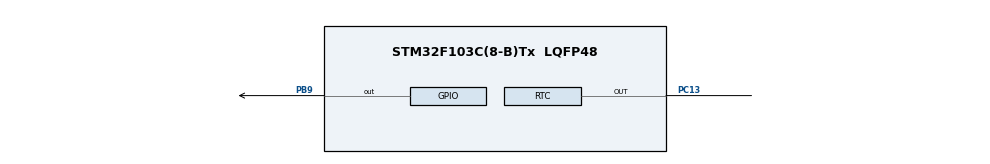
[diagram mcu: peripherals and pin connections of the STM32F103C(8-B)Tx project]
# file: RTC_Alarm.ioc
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Mcu.Family=STM32F1
Mcu.Name=STM32F103C(8-B)Tx
Mcu.Package=LQFP48
NVIC.PriorityGroup=NVIC_PRIORITYGROUP_4
NVIC.RTC_Alarm_IRQn=true\:0\:0\:false\:false\:true\:true
PA13.Mode=Serial_Wire
PA13.Signal=SYS_JTMS-SWDIO
PA14.Mode=Serial_Wire
PA14.Signal=SYS_JTCK-SWCLK
PB9.GPIO_ModeDefaultOutputPP=GPIO_MODE_OUTPUT_PP
PB9.GPIO_PuPd=GPIO_NOPULL
PB9.GPIO_Speed=GPIO_SPEED_FREQ_HIGH
PB9.PinState=GPIO_PIN_SET
PB9.Signal=GPIO_Output
PC13-TAMPER-RTC.Mode=RTC OUT
PC13-TAMPER-RTC.Signal=RTC_OUT
PD0-OSC_IN.Mode=HSE-External-Oscillator
PD0-OSC_IN.Signal=RCC_OSC_IN
PD1-OSC_OUT.Mode=HSE-External-Oscillator
PD1-OSC_OUT.Signal=RCC_OSC_OUT
ProjectManager.HeapSize=0x400
ProjectManager.StackSize=0x600
ProjectManager.TargetToolchain=MDK-ARM V5
RCC.AHBFreq_Value=72000000
RCC.APB1CLKDivider=RCC_HCLK_DIV2
RCC.APB1Freq_Value=36000000
RCC.APB1TimFreq_Value=72000000
RCC.APB2Freq_Value=72000000
RCC.APB2TimFreq_Value=72000000
RCC.EnbaleCSS=true
RCC.HCLKFreq_Value=72000000
RCC.HSE_VALUE=12000000
RCC.PLLMUL=RCC_PLL_MUL6
RCC.PLLSourceVirtual=RCC_PLLSOURCE_HSE
RCC.PREFETCH_ENABLE=1
RCC.SYSCLKFreq_VALUE=72000000
RCC.SYSCLKSource=RCC_SYSCLKSOURCE_PLLCLK
RCC.USBFreq_Value=72000000
RTC.Date=19
RTC.Format=RTC_FORMAT_BCD
RTC.Hours=12
RTC.Hours_A-RTC\ OUT=12
RTC.Month=RTC_MONTH_DECEMBER
RTC.OutPut=RTC_OUTPUTSOURCE_ALARM
RTC.Seconds_A-RTC\ OUT=10
RTC.WeekDay=RTC_WEEKDAY_WEDNESDAY
VP_RTC_VS_RTC_Activate.Mode=RTC_Enabled
VP_RTC_VS_RTC_Calendar.Mode=RTC_Calendar
board=custom

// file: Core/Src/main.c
/* USER CODE BEGIN Header */
/**
  ******************************************************************************
  * @file           : main.c
  * @brief          : Main program body
  ******************************************************************************
  ** This notice applies to any and all portions of this file
  * that are not between comment pairs USER CODE BEGIN and
  * USER CODE END. Other portions of this file, whether
  * inserted by the user or by software development tools
  * are owned by their respective copyright owners.
  *
  * COPYRIGHT(c) 2018 STMicroelectronics
  *
  * Redistribution and use in source and binary forms, with or without modification,
  * are permitted provided that the following conditions are met:
  *   1. Redistributions of source code must retain the above copyright notice,
  *      this list of conditions and the following disclaimer.
  *   2. Redistributions in binary form must reproduce the above copyright notice,
  *      this list of conditions and the following disclaimer in the documentation
  *      and/or other materials provided with the distribution.
  *   3. Neither the name of STMicroelectronics nor the names of its contributors
  *      may be used to endorse or promote products derived from this software
  *      without specific prior written permission.
  *
  * THIS SOFTWARE IS PROVIDED BY THE COPYRIGHT HOLDERS AND CONTRIBUTORS "AS IS"
  * AND ANY EXPRESS OR IMPLIED WARRANTIES, INCLUDING, BUT NOT LIMITED TO, THE
  * IMPLIED WARRANTIES OF MERCHANTABILITY AND FITNESS FOR A PARTICULAR PURPOSE ARE
  * DISCLAIMED. IN NO EVENT SHALL THE COPYRIGHT HOLDER OR CONTRIBUTORS BE LIABLE
  * FOR ANY DIRECT, INDIRECT, INCIDENTAL, SPECIAL, EXEMPLARY, OR CONSEQUENTIAL
  * DAMAGES (INCLUDING, BUT NOT LIMITED TO, PROCUREMENT OF SUBSTITUTE GOODS OR
  * SERVICES; LOSS OF USE, DATA, OR PROFITS; OR BUSINESS INTERRUPTION) HOWEVER
  * CAUSED AND ON ANY THEORY OF LIABILITY, WHETHER IN CONTRACT, STRICT LIABILITY,
  * OR TORT (INCLUDING NEGLIGENCE OR OTHERWISE) ARISING IN ANY WAY OUT OF THE USE
  * OF THIS SOFTWARE, EVEN IF ADVISED OF THE POSSIBILITY OF SUCH DAMAGE.
  *
  ******************************************************************************
  */
/* USER CODE END Header */

#include "main.h"
#include "rtc.h"
#include "gpio.h"

/* USER CODE BEGIN PV */
RTC_TimeTypeDef Time;
RTC_DateTypeDef Date;
/* USER CODE END PV */

void SystemClock_Config(void);

int main(void)
{

  /* MCU Configuration--------------------------------------------------------*/

  /* Reset of all peripherals, Initializes the Flash interface and the Systick. */
  HAL_Init();

  /* Configure the system clock */
  SystemClock_Config();

  /* Initialize all configured peripherals */
  MX_GPIO_Init();
  MX_RTC_Init();
  /* USER CODE BEGIN 2 */
		LL_mDelay(100);
  LL_GPIO_SetOutputPin(GPIOB,GPIO_PIN_9);
		LL_mDelay(100);
		LL_GPIO_ResetOutputPin(GPIOB,GPIO_PIN_9);
		LL_mDelay(100);
  LL_GPIO_SetOutputPin(GPIOB,GPIO_PIN_9);
		LL_mDelay(100);
		LL_GPIO_ResetOutputPin(GPIOB,GPIO_PIN_9);
  /* USER CODE END 2 */

  /* Infinite loop */
  /* USER CODE BEGIN WHILE */
  while (1)
  {
//			HAL_RTC_GetDate(&hrtc,&Date,RTC_FORMAT_BCD);
   HAL_RTC_GetTime(&hrtc,&Time,RTC_FORMAT_BCD);
    /* USER CODE END WHILE */

  }
}

void SystemClock_Config(void)
{
  LL_FLASH_SetLatency(LL_FLASH_LATENCY_2);

   if(LL_FLASH_GetLatency() != LL_FLASH_LATENCY_2)
  {
    Error_Handler();
  }
  LL_RCC_HSE_Enable();

   /* Wait till HSE is ready */
  while(LL_RCC_HSE_IsReady() != 1)
  {

  }
  LL_RCC_LSI_Enable();

   /* Wait till LSI is ready */
  while(LL_RCC_LSI_IsReady() != 1)
  {

  }
  LL_PWR_EnableBkUpAccess();
  LL_RCC_ForceBackupDomainReset();
  LL_RCC_ReleaseBackupDomainReset();
  LL_RCC_SetRTCClockSource(LL_RCC_RTC_CLKSOURCE_LSI);
  LL_RCC_EnableRTC();
  LL_RCC_HSE_EnableCSS();
  LL_RCC_PLL_ConfigDomain_SYS(LL_RCC_PLLSOURCE_HSE_DIV_1, LL_RCC_PLL_MUL_6);
  LL_RCC_PLL_Enable();

   /* Wait till PLL is ready */
  while(LL_RCC_PLL_IsReady() != 1)
  {

  }
  LL_RCC_SetAHBPrescaler(LL_RCC_SYSCLK_DIV_1);
  LL_RCC_SetAPB1Prescaler(LL_RCC_APB1_DIV_2);
  LL_RCC_SetAPB2Prescaler(LL_RCC_APB2_DIV_1);
  LL_RCC_SetSysClkSource(LL_RCC_SYS_CLKSOURCE_PLL);

   /* Wait till System clock is ready */
  while(LL_RCC_GetSysClkSource() != LL_RCC_SYS_CLKSOURCE_STATUS_PLL)
  {

  }
  LL_Init1msTick(72000000);
  LL_SYSTICK_SetClkSource(LL_SYSTICK_CLKSOURCE_HCLK);
  LL_SetSystemCoreClock(72000000);
}

/* USER CODE BEGIN 4 */
void HAL_RTC_AlarmAEventCallback(RTC_HandleTypeDef *hrtc)
{
  LL_GPIO_SetOutputPin(GPIOB,GPIO_PIN_9);
}
/* USER CODE END 4 */

void Error_Handler(void)
{
}

/************************ (C) COPYRIGHT STMicroelectronics *****END OF FILE****/
